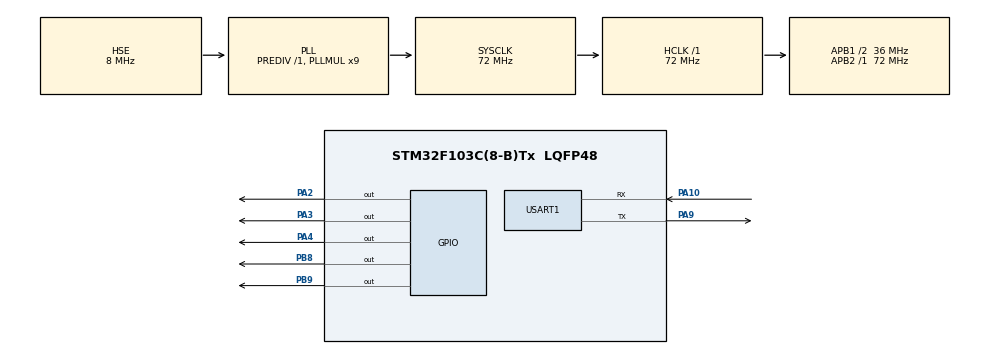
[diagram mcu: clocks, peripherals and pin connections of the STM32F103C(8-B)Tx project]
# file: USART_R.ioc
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Mcu.Family=STM32F1
Mcu.Name=STM32F103C(8-B)Tx
Mcu.Package=LQFP48
NVIC.PriorityGroup=NVIC_PRIORITYGROUP_4
NVIC.USART1_IRQn=true\:0\:0\:false\:false\:true\:true\:true\:true
PA10.Mode=Asynchronous
PA10.Signal=USART1_RX
PA13.Mode=Serial_Wire
PA13.Signal=SYS_JTMS-SWDIO
PA14.Mode=Serial_Wire
PA14.Signal=SYS_JTCK-SWCLK
PA2.GPIO_ModeDefaultOutputPP=GPIO_MODE_OUTPUT_PP
PA2.Signal=GPIO_Output
PA3.GPIO_ModeDefaultOutputPP=GPIO_MODE_OUTPUT_PP
PA3.Signal=GPIO_Output
PA4.GPIO_ModeDefaultOutputPP=GPIO_MODE_OUTPUT_PP
PA4.Signal=GPIO_Output
PA9.Mode=Asynchronous
PA9.Signal=USART1_TX
PB8.GPIO_ModeDefaultOutputPP=GPIO_MODE_OUTPUT_OD
PB8.GPIO_PuPd=GPIO_NOPULL
PB8.Signal=GPIO_Output
PB9.GPIO_ModeDefaultOutputPP=GPIO_MODE_OUTPUT_OD
PB9.GPIO_PuPd=GPIO_NOPULL
PB9.Signal=GPIO_Output
PD0-OSC_IN.Mode=HSE-External-Oscillator
PD0-OSC_IN.Signal=RCC_OSC_IN
PD1-OSC_OUT.Mode=HSE-External-Oscillator
PD1-OSC_OUT.Signal=RCC_OSC_OUT
ProjectManager.HeapSize=0x200
ProjectManager.StackSize=0x400
ProjectManager.TargetToolchain=CMake
RCC.AHBFreq_Value=72000000
RCC.APB1CLKDivider=RCC_HCLK_DIV2
RCC.APB1Freq_Value=36000000
RCC.APB1TimFreq_Value=72000000
RCC.APB2Freq_Value=72000000
RCC.APB2TimFreq_Value=72000000
RCC.HCLKFreq_Value=72000000
RCC.PLLMUL=RCC_PLL_MUL9
RCC.PLLSourceVirtual=RCC_PLLSOURCE_HSE
RCC.SYSCLKFreq_VALUE=72000000
RCC.SYSCLKSource=RCC_SYSCLKSOURCE_PLLCLK
RCC.USBFreq_Value=72000000
USART1.VirtualMode=VM_ASYNC
board=custom

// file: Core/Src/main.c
/* USER CODE BEGIN Header */
/**
  ******************************************************************************
  * @file           : main.c
  * @brief          : Main program body
  ******************************************************************************
  * @attention
  *
  * Copyright (c) 2026 STMicroelectronics.
  * All rights reserved.
  *
  * This software is licensed under terms that can be found in the LICENSE file
  * in the root directory of this software component.
  * If no LICENSE file comes with this software, it is provided AS-IS.
  *
  ******************************************************************************
  */
/* USER CODE END Header */
#include "main.h"
#include "usart.h"
#include "gpio.h"

/* USER CODE BEGIN Includes */
#include "OLED.h"
/* USER CODE END Includes */
#define False 0
#define True  1

void SystemClock_Config(void);
/* USER CODE BEGIN PFP */
uint8_t NonBlocking_DelayCheck(uint32_t start_time, uint32_t delay_ms) {
  // 处理HAL_GetTick()溢出（比如从0xFFFFFFFF回到0的情况）
  if (HAL_GetTick() - start_time >= delay_ms) {
    return 1; // 延迟时间已到
  }
  return 0; // 延迟未到
}
/* USER CODE END PFP */

/* USER CODE BEGIN 0 */
// 全局变量定义
uint8_t receiveDate[2] = {0};
volatile uint8_t uart1_received = 0;  // 接收完成标志，volatile确保多线程安全
volatile uint8_t uart1_need_response = 0;  // 需要回传标志
uint32_t display_start_time = 0;
uint8_t need_clear_message_date = 0;
uint8_t need_clear_message_IT = 0;
char display_msg[20] = {0};  // 存储显示消息

void HAL_UART_RxCpltCallback(UART_HandleTypeDef *huart) {
  if (huart->Instance == USART1) {
    uart1_received =         1;
    uart1_need_response =    1;
    HAL_UART_Receive_IT(&huart1, receiveDate, sizeof(receiveDate));
  }
}

void HAL_UART_TxCpltCallback(UART_HandleTypeDef *huart) {
  if (huart->Instance == USART1) {
    OLED_ShowString(3, 1, "Tx_Is_OK");
  }
}

/**
  * @brief  应用入口函数
  * @retval int
  */
int main(void) {
  /* MCU初始化 */
  HAL_Init();
  SystemClock_Config();
  MX_GPIO_Init();
  MX_USART1_UART_Init();

  /* 外设初始化 */
  OLED_Init();
  OLED_ShowString(1, 1, "USART Receive...");

  HAL_UART_Receive_IT(&huart1, receiveDate, sizeof(receiveDate));

  while (1) {
    // 1. 检查是否接收到新数据
    if (uart1_received) {
      uart1_received = 0;  // 清除标志

      // 显示接收到的数据
      OLED_ShowString(2, 1, display_msg);

      // 设置显示成功消息
      OLED_ShowString(2, 1, "ReceiveDateOK");
      display_start_time = HAL_GetTick();
      need_clear_message_date = 1;
      need_clear_message_IT = 1;

      // 根据接收到的数据控制GPIO
      if (receiveDate[0] == 'R') {
        HAL_GPIO_WritePin(GPIOA, GPIO_PIN_4,
                         (receiveDate[1] == '0') ? GPIO_PIN_SET : GPIO_PIN_RESET);
      } else if (receiveDate[0] == 'G') {
        HAL_GPIO_WritePin(GPIOA, GPIO_PIN_2,
                         (receiveDate[1] == '0') ? GPIO_PIN_SET : GPIO_PIN_RESET);
      } else if (receiveDate[0] == 'B') {
        HAL_GPIO_WritePin(GPIOA, GPIO_PIN_3,
                         (receiveDate[1] == '0') ? GPIO_PIN_SET : GPIO_PIN_RESET);
      }
    }

    // 2. 检查是否需要回传数据（使用中断发送）
    if (uart1_need_response) {
      uart1_need_response = False;
      // 检查串口状态是否就绪
      if (huart1.gState == HAL_UART_STATE_READY) {
        // 使用中断方式回传数据（非阻塞）
        HAL_UART_Transmit_IT(&huart1, receiveDate, sizeof(receiveDate));
      }
    }

    // 3. 检查是否该清除"ReceiveDateOK"消息
    if (need_clear_message_date && NonBlocking_DelayCheck(display_start_time, 1000)) {
      OLED_ShowString(2, 1, "                ");
      need_clear_message_date = 0;
    }

    // 4. 检查是否要清除"Tx_Is_OK"消息
    if (need_clear_message_IT && NonBlocking_DelayCheck(display_start_time , 500)) {
      OLED_ShowString(3, 1, "                ");
      need_clear_message_IT = 0;
    }
  }
}

void SystemClock_Config(void)
{
  RCC_OscInitTypeDef RCC_OscInitStruct = {0};
  RCC_ClkInitTypeDef RCC_ClkInitStruct = {0};

  /** Initializes the RCC Oscillators according to the specified parameters
  * in the RCC_OscInitTypeDef structure.
  */
  RCC_OscInitStruct.OscillatorType = RCC_OSCILLATORTYPE_HSE;
  RCC_OscInitStruct.HSEState = RCC_HSE_ON;
  RCC_OscInitStruct.HSEPredivValue = RCC_HSE_PREDIV_DIV1;
  RCC_OscInitStruct.HSIState = RCC_HSI_ON;
  RCC_OscInitStruct.PLL.PLLState = RCC_PLL_ON;
  RCC_OscInitStruct.PLL.PLLSource = RCC_PLLSOURCE_HSE;
  RCC_OscInitStruct.PLL.PLLMUL = RCC_PLL_MUL9;
  if (HAL_RCC_OscConfig(&RCC_OscInitStruct) != HAL_OK)
  {
    Error_Handler();
  }

  /** Initializes the CPU, AHB and APB buses clocks
  */
  RCC_ClkInitStruct.ClockType = RCC_CLOCKTYPE_HCLK|RCC_CLOCKTYPE_SYSCLK
                              |RCC_CLOCKTYPE_PCLK1|RCC_CLOCKTYPE_PCLK2;
  RCC_ClkInitStruct.SYSCLKSource = RCC_SYSCLKSOURCE_PLLCLK;
  RCC_ClkInitStruct.AHBCLKDivider = RCC_SYSCLK_DIV1;
  RCC_ClkInitStruct.APB1CLKDivider = RCC_HCLK_DIV2;
  RCC_ClkInitStruct.APB2CLKDivider = RCC_HCLK_DIV1;

  if (HAL_RCC_ClockConfig(&RCC_ClkInitStruct, FLASH_LATENCY_2) != HAL_OK)
  {
    Error_Handler();
  }
}

void Error_Handler(void)
{
  __disable_irq();
  while (1)
  {
  }
}
